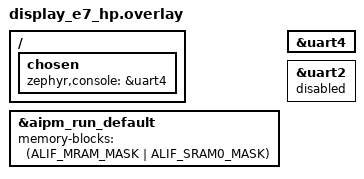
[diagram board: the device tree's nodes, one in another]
/* Copyright (C) 2026 Alif Semiconductor - All Rights Reserved.
 * Use, distribution and modification of this code is permitted under the
 * terms stated in the Alif Semiconductor Software License Agreement
 *
 * You should have received a copy of the Alif Semiconductor Software
 * License Agreement with this file. If not, please write to:
 * contact@alifsemi.com, or visit: https://alifsemi.com/license
 *
 */

#include "pm_mram_hp.overlay"

&aipm_run_default {
	memory-blocks   = <(ALIF_MRAM_MASK | ALIF_SRAM0_MASK)>;
};

&uart4 {
	status = "okay";
};

&uart2 {
	status = "disabled";
};

/ {
	chosen {
		zephyr,console = &uart4;
	};
};
